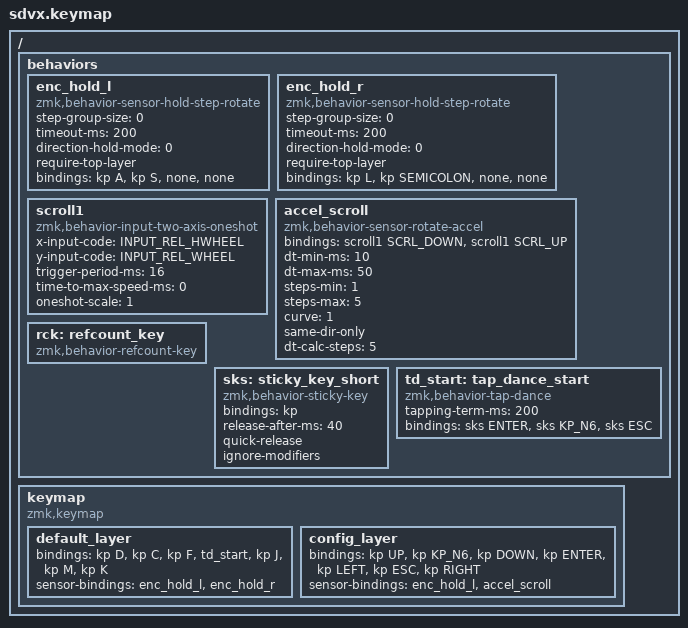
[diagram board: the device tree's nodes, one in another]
#include <behaviors.dtsi>
#include <dt-bindings/zmk/keys.h>
#include <dt-bindings/zmk/outputs.h>
#include <dt-bindings/zmk/mouse.h>
#include <dt-bindings/zmk/pointing.h>

/ {
    behaviors{
        enc_hold_l: enc_hold_l {
            compatible = "zmk,behavior-sensor-hold-step-rotate";
            #sensor-binding-cells = <0>;
            step-group-size = <0>;
            timeout-ms = <200>;
            direction-hold-mode = <0>;

            require-top-layer;


            bindings = <
                &kp A   /* hold_cw  */
                &kp S   /* hold_ccw */
                &none    /* step_cw  */
                &none   /* step_ccw */
            >;
        };
        enc_hold_r: enc_hold_r {
            compatible = "zmk,behavior-sensor-hold-step-rotate";
            #sensor-binding-cells = <0>;
            step-group-size = <0>;
            timeout-ms = <200>;
            direction-hold-mode = <0>;

            require-top-layer;

            bindings = <
                &kp L   /* hold_cw  */
                &kp SEMICOLON   /* hold_ccw */
                &none    /* step_cw  */
                &none   /* step_ccw */
            >;
        };

        scroll1: scroll1 {
            compatible = "zmk,behavior-input-two-axis-oneshot";
            #binding-cells = <1>;

            x-input-code = <INPUT_REL_HWHEEL>;
            y-input-code = <INPUT_REL_WHEEL>;

            trigger-period-ms = <16>;
            time-to-max-speed-ms = <0>;

            oneshot-scale = <1>;
        };

        accel_scroll: accel_scroll {
            compatible = "zmk,behavior-sensor-rotate-accel";
            #sensor-binding-cells = <0>;

            // cw / ccw
            bindings = <&scroll1 SCRL_DOWN>, <&scroll1 SCRL_UP>;

            dt-min-ms = <10>;
            dt-max-ms = <50>;

            steps-min = <1>;
            steps-max = <5>;    // 要望どおり上限5

            curve = <1>;        // 0=linear, 1=quad, 2=cubic
            same-dir-only;      // 逆回転で加速リセットしたいならON
            dt-calc-steps = <5>;
        };

        rck: refcount_key {
            compatible = "zmk,behavior-refcount-key";
            #binding-cells = <1>;
        };

        sks: sticky_key_short {
            compatible = "zmk,behavior-sticky-key";
            #binding-cells = <1>;
            bindings = <&kp>;
            release-after-ms = <40>;
            quick-release;
            ignore-modifiers;
        };

        td_start: tap_dance_start {
            compatible = "zmk,behavior-tap-dance";
            #binding-cells = <0>;
            tapping-term-ms = <200>;
            bindings = <&sks ENTER>, <&sks KP_N6>, <&sks ESC>;
        };
    };

        
    keymap {
        compatible = "zmk,keymap";
        default_layer {
            bindings = <
                &kp D &kp C  &kp F  &td_start  &kp J  &kp M  &kp K
            >;
            sensor-bindings = <&enc_hold_l &enc_hold_r>;
        };

   config_layer {
            bindings = <
                &kp UP &kp KP_N6  &kp DOWN  &kp ENTER  &kp LEFT  &kp ESC  &kp RIGHT
            >;
            sensor-bindings = <&enc_hold_l &accel_scroll>;
        };
    };
};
